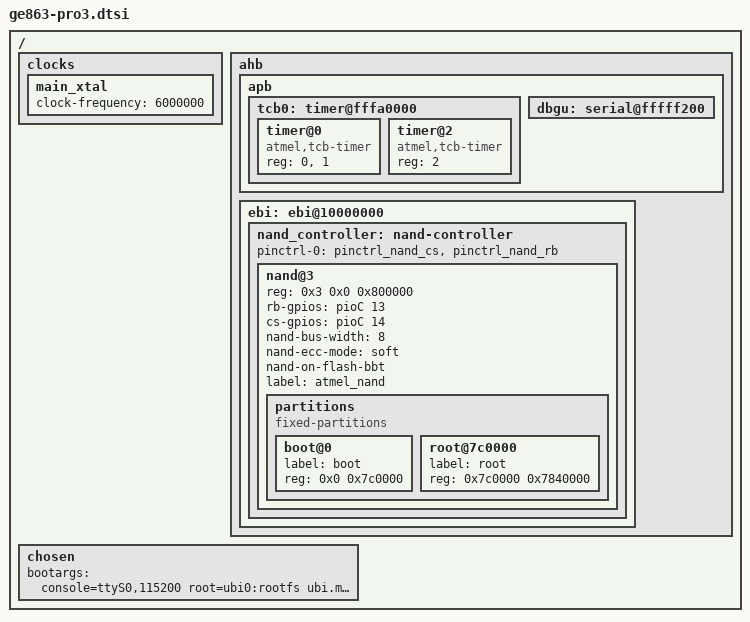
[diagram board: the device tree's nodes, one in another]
/*
 * ge863_pro3.dtsi - Device Tree file for Telit GE863-PRO3
 *
 * Copyright (C) 2012 Telit,
 *               2012 Fabio Porcedda <fabio.porcedda@gmail.com>
 *
 * Licensed under GPLv2 or later.
 */

#include "at91sam9260.dtsi"

/ {
	clocks {
		main_xtal {
			clock-frequency = <6000000>;
		};
	};

	ahb {
		apb {
			tcb0: timer@fffa0000 {
				timer@0 {
					compatible = "atmel,tcb-timer";
					reg = <0>, <1>;
				};

				timer@2 {
					compatible = "atmel,tcb-timer";
					reg = <2>;
				};
			};

			dbgu: serial@fffff200 {
				status = "okay";
			};
		};

		ebi: ebi@10000000 {
			status = "okay";

			nand_controller: nand-controller {
				status = "okay";
				pinctrl-0 = <&pinctrl_nand_cs &pinctrl_nand_rb>;
				pinctrl-names = "default";

				nand@3 {
					reg = <0x3 0x0 0x800000>;
					rb-gpios = <&pioC 13 GPIO_ACTIVE_HIGH>;
					cs-gpios = <&pioC 14 GPIO_ACTIVE_HIGH>;
					nand-bus-width = <8>;
					nand-ecc-mode = "soft";
					nand-on-flash-bbt;
					label = "atmel_nand";

					partitions {
						compatible = "fixed-partitions";
						#address-cells = <1>;
						#size-cells = <1>;

						boot@0 {
							label = "boot";
							reg = <0x0 0x7c0000>;
						};

						root@7c0000 {
							label = "root";
							reg = <0x7c0000 0x7840000>;
						};
					};
				};
			};
		};
	};

	chosen {
		bootargs = "console=ttyS0,115200 root=ubi0:rootfs ubi.mtd=1 rootfstype=ubifs";
	};
};
